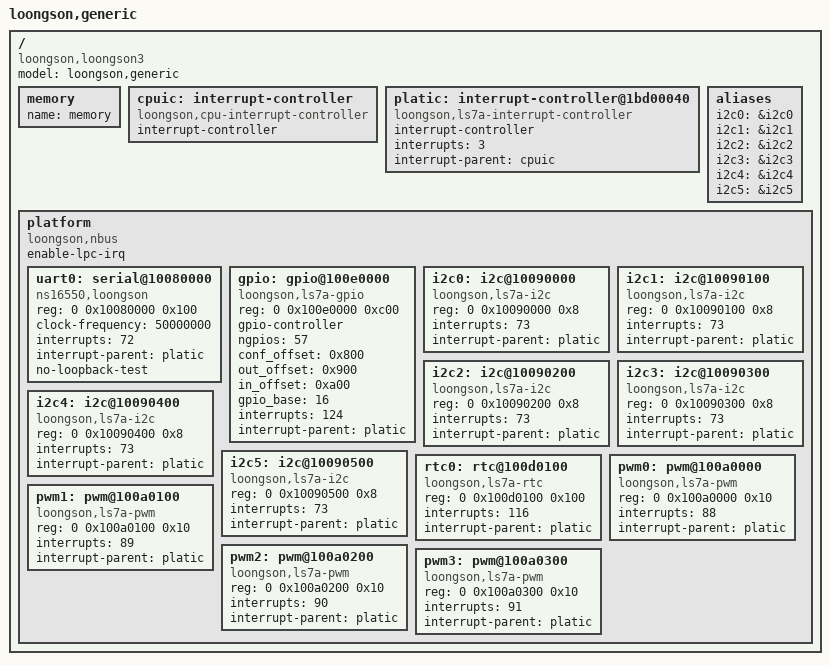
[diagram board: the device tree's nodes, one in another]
/dts-v1/;
#include "loongson3.dtsi"
/ {
	model = "loongson,generic";
	compatible = "loongson,loongson3";
	#address-cells = <2>;
	#size-cells = <2>;

	memory {
		name = "memory";
		device_type = "memory";
	};

	cpuic: interrupt-controller {
		compatible = "loongson,cpu-interrupt-controller";
		interrupt-controller;
		#interrupt-cells = <1>;
	};

	platic: interrupt-controller@1bd00040 {
		compatible = "loongson,ls7a-interrupt-controller";
		interrupt-controller;
		#interrupt-cells = <1>;
		interrupts = <3>;
		interrupt-parent = <&cpuic>;
	};

	aliases {
		i2c0 = &i2c0;
		i2c1 = &i2c1;
		i2c2 = &i2c2;
		i2c3 = &i2c3;
		i2c4 = &i2c4;
		i2c5 = &i2c5;
	};

	platform {
		compatible = "loongson,nbus", "simple-bus";
		#address-cells = <2>;
		#size-cells = <1>;
		enable-lpc-irq;
		ranges = <0x000 0x00000000 0x000 0x00000000 0x20000000
			  0x000 0x40000000 0x000 0x40000000 0x40000000
			  0xe00 0x00000000 0xe00 0x00000000 0x80000000>;

		uart0: serial@10080000 {
			device_type = "serial";
			compatible = "ns16550,loongson";
			reg = <0 0x10080000 0x100>;
			clock-frequency = <50000000>;
			interrupts = <72>;
			interrupt-parent = <&platic>;
			no-loopback-test;
		};

		gpio: gpio@100e0000 {
			compatible = "loongson,ls7a-gpio";
			reg = <0 0x100e0000 0xc00>;
			gpio-controller;
			#gpio-cells = <2>;
			ngpios = <57>;
			conf_offset = <0x800>;
			out_offset = <0x900>;
			in_offset = <0xa00>;
			gpio_base = <16>;
			interrupts = <124>;
			interrupt-parent = <&platic>;
		};

		i2c0: i2c@10090000 {
			compatible = "loongson,ls7a-i2c";
			reg = <0 0x10090000 0x8>;
			interrupts = <73>;
			interrupt-parent = <&platic>;
			#address-cells = <1>;
			#size-cells = <0>;
		};

		i2c1: i2c@10090100 {
			compatible = "loongson,ls7a-i2c";
			reg = <0 0x10090100 0x8>;
			interrupts = <73>;
			interrupt-parent = <&platic>;
			#address-cells = <1>;
			#size-cells = <0>;
		};

		i2c2: i2c@10090200 {
			compatible = "loongson,ls7a-i2c";
			reg = <0 0x10090200 0x8>;
			interrupts = <73>;
			interrupt-parent = <&platic>;
			#address-cells = <1>;
			#size-cells = <0>;
		};

		i2c3: i2c@10090300 {
			compatible = "loongson,ls7a-i2c";
			reg = <0 0x10090300 0x8>;
			interrupts = <73>;
			interrupt-parent = <&platic>;
			#address-cells = <1>;
			#size-cells = <0>;
		};

		i2c4: i2c@10090400 {
			compatible = "loongson,ls7a-i2c";
			reg = <0 0x10090400 0x8>;
			interrupts = <73>;
			interrupt-parent = <&platic>;
			#address-cells = <1>;
			#size-cells = <0>;
		};

		i2c5: i2c@10090500 {
			compatible = "loongson,ls7a-i2c";
			reg = <0 0x10090500 0x8>;
			interrupts = <73>;
			interrupt-parent = <&platic>;
			#address-cells = <1>;
			#size-cells = <0>;
		};

		rtc0: rtc@100d0100 {
			compatible = "loongson,ls7a-rtc";
			reg = <0 0x100d0100 0x100>;
			interrupts = <116>;
			interrupt-parent = <&platic>;
		};

                pwm0: pwm@100a0000 {
                        compatible = "loongson,ls7a-pwm";
                        reg = <0 0x100a0000 0x10>;
                        interrupts = <88>;
                        interrupt-parent = <&platic>;
                };

                pwm1: pwm@100a0100 {
                        compatible = "loongson,ls7a-pwm";
                        reg = <0 0x100a0100 0x10>;
                        interrupts = <89>;
                        interrupt-parent = <&platic>;
                };

                pwm2: pwm@100a0200 {
                        compatible = "loongson,ls7a-pwm";
                        reg = <0 0x100a0200 0x10>;
                        interrupts = <90>;
                        interrupt-parent = <&platic>;
                };

                pwm3: pwm@100a0300 {
                        compatible = "loongson,ls7a-pwm";
                        reg = <0 0x100a0300 0x10>;
                        interrupts = <91>;
                        interrupt-parent = <&platic>;
                };
	};
};
